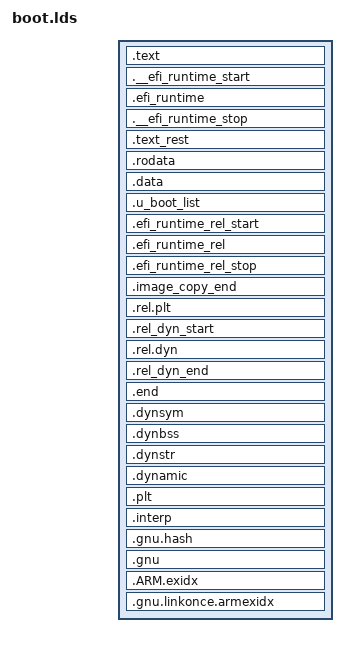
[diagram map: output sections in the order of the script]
/* SPDX-License-Identifier: GPL-2.0+ */
/*
 * Copyright (c) 2004-2008 Texas Instruments
 *
 * (C) Copyright 2002
 * Gary Jennejohn, DENX Software Engineering, <garyj@denx.de>
 */


OUTPUT_FORMAT("elf32-littlearm", "elf32-littlearm", "elf32-littlearm")
OUTPUT_ARCH(arm)
ENTRY(_start)
SECTIONS
{
	. = 0x00000000;

	. = ALIGN(4);
	.text :
	{
		*(.__image_copy_start)
		*(.text*)
	}

	/* This needs to come before *(.text*) */
	.__efi_runtime_start : {
		*(.__efi_runtime_start)
	}

	.efi_runtime : {
		*(.text.efi_runtime*)
		*(.rodata.efi_runtime*)
		*(.data.efi_runtime*)
	}

	.__efi_runtime_stop : {
		*(.__efi_runtime_stop)
	}

	.text_rest :
	{
		*(.text*)
	}

	. = ALIGN(4);
	.rodata : { *(SORT_BY_ALIGNMENT(SORT_BY_NAME(.rodata*))) }

	. = ALIGN(4);
	.data : {
		*(.data*)
	}

	. = ALIGN(4);

	. = .;

	. = ALIGN(4);
	.u_boot_list : {
		KEEP(*(SORT(.u_boot_list*)));
	}

	. = ALIGN(4);

	.efi_runtime_rel_start :
	{
		*(.__efi_runtime_rel_start)
	}

	.efi_runtime_rel : {
		*(.rel*.efi_runtime)
		*(.rel*.efi_runtime.*)
	}

	.efi_runtime_rel_stop :
	{
		*(.__efi_runtime_rel_stop)
	}

	. = ALIGN(4);

	.image_copy_end :
	{
		*(.__image_copy_end)
	}

	.rel.plt :
	{
		*(.rel.plt)
	}

	.rel_dyn_start :
	{
		*(.__rel_dyn_start)
	}

	.rel.dyn : {
		*(.rel*)
	}

	.rel_dyn_end :
	{
		*(.__rel_dyn_end)
	}

	.end :
	{
		*(.__end)
	}

	_image_binary_end = .;


	.dynsym _image_binary_end : { *(.dynsym) }
	.dynbss : { *(.dynbss) }
	.dynstr : { *(.dynstr*) }
	.dynamic : { *(.dynamic*) }
	.plt : { *(.plt*) }
	.interp : { *(.interp*) }
	.gnu.hash : { *(.gnu.hash) }
	.gnu : { *(.gnu*) }
	.ARM.exidx : { *(.ARM.exidx*) }
	.gnu.linkonce.armexidx : { *(.gnu.linkonce.armexidx.*) }
}
